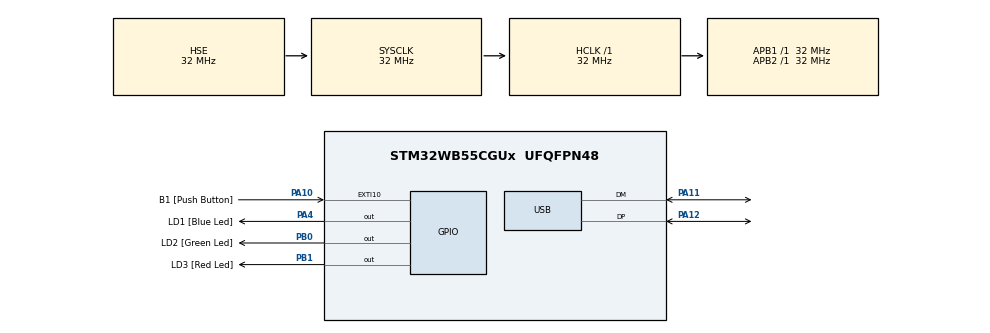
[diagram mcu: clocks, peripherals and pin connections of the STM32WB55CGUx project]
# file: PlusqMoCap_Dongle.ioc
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Mcu.Family=STM32WB
Mcu.Name=STM32WB55CGUx
Mcu.Package=UFQFPN48
NVIC.EXTI15_10_IRQn=true\:0\:0\:false\:false\:true\:true\:true
NVIC.PriorityGroup=NVIC_PRIORITYGROUP_4
NVIC.RTC_WKUP_IRQn=true\:0\:0\:false\:false\:true\:true\:true
NVIC.USB_HP_IRQn=true\:0\:0\:false\:false\:true\:true\:true
NVIC.USB_LP_IRQn=true\:0\:0\:false\:false\:true\:false\:true
OSC_IN.Mode=HSE-External-Oscillator
OSC_IN.Signal=RCC_OSC_IN
OSC_OUT.Mode=HSE-External-Oscillator
OSC_OUT.Signal=RCC_OSC_OUT
PA10.GPIO_Label=B1 [Push Button]
PA10.GPIO_ModeDefaultEXTI=GPIO_MODE_IT_FALLING
PA10.GPIO_PuPd=GPIO_PULLUP
PA10.Signal=GPXTI10
PA11.Mode=Device
PA11.Signal=USB_DM
PA12.Mode=Device
PA12.Signal=USB_DP
PA13.GPIO_Label=JTMS
PA13.Mode=Trace_Asynchronous_SW
PA13.Signal=SYS_JTMS-SWDIO
PA14.GPIO_Label=JTCK
PA14.Mode=Trace_Asynchronous_SW
PA14.Signal=SYS_JTCK-SWCLK
PA4.GPIO_Label=LD1 [Blue Led]
PA4.Signal=GPIO_Output
PB0.GPIO_Label=LD2 [Green Led]
PB0.Signal=GPIO_Output
PB1.GPIO_Label=LD3 [Red Led]
PB1.Signal=GPIO_Output
PB3.GPIO_Label=JTDO
PB3.Mode=Trace_Asynchronous_SW
PB3.Signal=SYS_JTDO-SWO
PC14-OSC32_IN.Mode=LSE-External-Oscillator
PC14-OSC32_IN.Signal=RCC_OSC32_IN
PC15-OSC32_OUT.Mode=LSE-External-Oscillator
PC15-OSC32_OUT.Signal=RCC_OSC32_OUT
ProjectManager.HeapSize=0x200
ProjectManager.StackSize=0x400
ProjectManager.TargetToolchain=STM32CubeIDE
RCC.ADCFreq_Value=160000000
RCC.AHBFreq_Value=32000000
RCC.APB1Freq_Value=32000000
RCC.APB1TimFreq_Value=32000000
RCC.APB2Freq_Value=32000000
RCC.APB2TimFreq_Value=32000000
RCC.APB3Freq_Value=16000000
RCC.CK48CLockSelection=RCC_USBCLKSOURCE_HSI48
RCC.CortexFreq_Value=32000000
RCC.HCLKFreq_Value=32000000
RCC.HSE_VALUE=32000000
RCC.HSI48_VALUE=48000000
RCC.HSI_VALUE=16000000
RCC.PLLM=RCC_PLLM_DIV2
RCC.PLLN=16
RCC.PLLQ=RCC_PLLQ_DIV4
RCC.PLLSAI1N=20
RCC.PLLSAI1Q=RCC_PLLQ_DIV5
RCC.PLLSourceVirtual=RCC_PLLSOURCE_HSE
RCC.RFWKPClockSelection=RCC_RFWKPCLKSOURCE_LSE
RCC.RTCClockSelection=RCC_RTCCLKSOURCE_LSE
RCC.SMPSCLockSelectionVirtual=RCC_SMPSCLKSOURCE_HSE
RCC.SMPSDivider=4
RCC.SYSCLKFreq_VALUE=32000000
RCC.SYSCLKSource=RCC_SYSCLKSOURCE_HSE
RCC.USBFreq_Value=48000000
RCC.VCOOutputFreq_Value=256000000
RF1.Mode=RF1_Activate
RF1.Signal=RF_RF1
STM32_WPAN.BLE_APPLICATION_TYPE=BLE_CLIENT_PROFILE
STM32_WPAN.CFG_FAST_CONN_ADV_INTERVAL_MAX_HEXA=0x0
STM32_WPAN.CFG_FAST_CONN_ADV_INTERVAL_MIN_HEXA=0x0
STM32_WPAN.CFG_LP_CONN_ADV_INTERVAL_MAX_HEXA=0x0
STM32_WPAN.CFG_LP_CONN_ADV_INTERVAL_MIN_HEXA=0x0
STM32_WPAN.LOCAL_NAME_FORMATTED=,'0'
USB.Sof_enable=DISABLE
USB_DEVICE.CLASS_NAME_FS=CDC
USB_DEVICE.VirtualMode=Cdc
USB_DEVICE.VirtualModeFS=Cdc_FS
VP_HSEM_VS_HSEM.Mode=HSEM_Activate
VP_RTC_VS_RTC_Activate.Mode=RTC_Enabled
VP_RTC_VS_RTC_WakeUp_intern.Mode=WakeUp
VP_STM32_WPAN_VS_BLE_HOST.Mode=STM32_WPAN_Enabled
VP_USB_DEVICE_VS_USB_DEVICE_CDC_FS.Mode=CDC_FS
board=P-NUCLEO-WB55-USBDongle

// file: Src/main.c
/* USER CODE BEGIN Header */
/**
  ******************************************************************************
  * @file           : main.c
  * @brief          : Main program body
  ******************************************************************************
  * @attention
  *
  * <h2><center>&copy; Copyright (c) 2019 STMicroelectronics.
  * All rights reserved.</center></h2>
  *
  * This software component is licensed by ST under BSD 3-Clause license,
  * the "License"; You may not use this file except in compliance with the
  * License. You may obtain a copy of the License at:
  *                        opensource.org/licenses/BSD-3-Clause
  *
  ******************************************************************************
  */
/* USER CODE END Header */

#include "main.h"
#include "app_entry.h"
//#include "usb_device.h"

/* USER CODE BEGIN Includes */
#include "vcp.h"
#include "scheduler.h"
#include "app_conf.h"
/* USER CODE END Includes */

RTC_HandleTypeDef hrtc;

/* USER CODE BEGIN PV */
uint8_t	usb_tx_buffer[2048], usb_rx_buffer[2048];
/* USER CODE END PV */

void SystemClock_Config(void);
static void MX_GPIO_Init(void);
static void MX_RF_Init(void);
static void MX_RTC_Init(void);
/* USER CODE BEGIN PFP */
//void dummy_callback(void)
//{
//
//}
/* USER CODE END PFP */

int main(void)
{

  /* MCU Configuration--------------------------------------------------------*/

  /* Reset of all peripherals, Initializes the Flash interface and the Systick. */
  HAL_Init();

  /* Configure the system clock */
  SystemClock_Config();

  /* Initialize all configured peripherals */
  MX_GPIO_Init();
  MX_RF_Init();
  MX_RTC_Init();
//  MX_USB_Device_Init();
  /* USER CODE BEGIN 2 */

  VCP_Init(usb_tx_buffer, usb_rx_buffer);

  /* USER CODE END 2 */
//  uint8_t test_text[] = "test!\n";
  APPE_Init();

  /* Infinite loop */
  /* USER CODE BEGIN WHILE */

  while (1)
  {

	  SCH_Run(~0);
    /* USER CODE END WHILE */

  }
}

void SystemClock_Config(void)
{
  RCC_OscInitTypeDef RCC_OscInitStruct = {0};
  RCC_ClkInitTypeDef RCC_ClkInitStruct = {0};
  RCC_PeriphCLKInitTypeDef PeriphClkInitStruct = {0};

  /** Configure LSE Drive Capability
  */
  __HAL_RCC_LSEDRIVE_CONFIG(RCC_LSEDRIVE_LOW);
  /** Configure the main internal regulator output voltage
  */
  __HAL_PWR_VOLTAGESCALING_CONFIG(PWR_REGULATOR_VOLTAGE_SCALE1);
  /** Initializes the CPU, AHB and APB busses clocks
  */
  RCC_OscInitStruct.OscillatorType = RCC_OSCILLATORTYPE_HSI48|RCC_OSCILLATORTYPE_HSI
                              |RCC_OSCILLATORTYPE_HSE|RCC_OSCILLATORTYPE_LSE;
  RCC_OscInitStruct.HSEState = RCC_HSE_ON;
  RCC_OscInitStruct.LSEState = RCC_LSE_ON;
  RCC_OscInitStruct.HSIState = RCC_HSI_ON;
  RCC_OscInitStruct.HSI48State = RCC_HSI48_ON;
  RCC_OscInitStruct.HSICalibrationValue = RCC_HSICALIBRATION_DEFAULT;
  RCC_OscInitStruct.PLL.PLLState = RCC_PLL_NONE;
  if (HAL_RCC_OscConfig(&RCC_OscInitStruct) != HAL_OK)
  {
    Error_Handler();
  }
  /** Configure the SYSCLKSource, HCLK, PCLK1 and PCLK2 clocks dividers
  */
  RCC_ClkInitStruct.ClockType = RCC_CLOCKTYPE_HCLK4|RCC_CLOCKTYPE_HCLK2
                              |RCC_CLOCKTYPE_HCLK|RCC_CLOCKTYPE_SYSCLK
                              |RCC_CLOCKTYPE_PCLK1|RCC_CLOCKTYPE_PCLK2;
  RCC_ClkInitStruct.SYSCLKSource = RCC_SYSCLKSOURCE_HSE;
  RCC_ClkInitStruct.AHBCLKDivider = RCC_SYSCLK_DIV1;
  RCC_ClkInitStruct.APB1CLKDivider = RCC_HCLK_DIV1;
  RCC_ClkInitStruct.APB2CLKDivider = RCC_HCLK_DIV1;
  RCC_ClkInitStruct.AHBCLK2Divider = RCC_SYSCLK_DIV1;
  RCC_ClkInitStruct.AHBCLK4Divider = RCC_SYSCLK_DIV1;

  if (HAL_RCC_ClockConfig(&RCC_ClkInitStruct, FLASH_LATENCY_1) != HAL_OK)
  {
    Error_Handler();
  }
  /** Initializes the peripherals clocks
  */
  PeriphClkInitStruct.PeriphClockSelection = RCC_PERIPHCLK_SMPS|RCC_PERIPHCLK_RFWAKEUP
                              |RCC_PERIPHCLK_RTC|RCC_PERIPHCLK_USB;
  PeriphClkInitStruct.UsbClockSelection = RCC_USBCLKSOURCE_HSI48;
  PeriphClkInitStruct.RTCClockSelection = RCC_RTCCLKSOURCE_LSE;
  PeriphClkInitStruct.RFWakeUpClockSelection = RCC_RFWKPCLKSOURCE_LSE;
  PeriphClkInitStruct.SmpsClockSelection = RCC_SMPSCLKSOURCE_HSE;
  PeriphClkInitStruct.SmpsDivSelection = RCC_SMPSCLKDIV_RANGE1;

  if (HAL_RCCEx_PeriphCLKConfig(&PeriphClkInitStruct) != HAL_OK)
  {
    Error_Handler();
  }
}

static void MX_RF_Init(void)
{

}

static void MX_RTC_Init(void)
{

  /** Initialize RTC Only
  */
  hrtc.Instance = RTC;
  hrtc.Init.HourFormat = RTC_HOURFORMAT_24;
  hrtc.Init.AsynchPrediv = 127;
  hrtc.Init.SynchPrediv = 255;
  hrtc.Init.OutPut = RTC_OUTPUT_DISABLE;
  hrtc.Init.OutPutRemap = RTC_OUTPUT_REMAP_NONE;
  hrtc.Init.OutPutPolarity = RTC_OUTPUT_POLARITY_HIGH;
  hrtc.Init.OutPutType = RTC_OUTPUT_TYPE_OPENDRAIN;
  if (HAL_RTC_Init(&hrtc) != HAL_OK)
  {
    Error_Handler();
  }
  /** Enable the WakeUp
  */
  if (HAL_RTCEx_SetWakeUpTimer_IT(&hrtc, 0, RTC_WAKEUPCLOCK_RTCCLK_DIV16) != HAL_OK)
  {
    Error_Handler();
  }

}

static void MX_GPIO_Init(void)
{
  GPIO_InitTypeDef GPIO_InitStruct = {0};

  /* GPIO Ports Clock Enable */
  __HAL_RCC_GPIOC_CLK_ENABLE();
  __HAL_RCC_GPIOA_CLK_ENABLE();
  __HAL_RCC_GPIOB_CLK_ENABLE();

  /*Configure GPIO pin Output Level */
  HAL_GPIO_WritePin(LD1_GPIO_Port, LD1_Pin, GPIO_PIN_RESET);

  /*Configure GPIO pin Output Level */
  HAL_GPIO_WritePin(GPIOB, LD2_Pin|LD3_Pin, GPIO_PIN_RESET);

  /*Configure GPIO pin : LD1_Pin */
  GPIO_InitStruct.Pin = LD1_Pin;
  GPIO_InitStruct.Mode = GPIO_MODE_OUTPUT_PP;
  GPIO_InitStruct.Pull = GPIO_NOPULL;
  GPIO_InitStruct.Speed = GPIO_SPEED_FREQ_LOW;
  HAL_GPIO_Init(LD1_GPIO_Port, &GPIO_InitStruct);

  /*Configure GPIO pins : LD2_Pin LD3_Pin */
  GPIO_InitStruct.Pin = LD2_Pin|LD3_Pin;
  GPIO_InitStruct.Mode = GPIO_MODE_OUTPUT_PP;
  GPIO_InitStruct.Pull = GPIO_NOPULL;
  GPIO_InitStruct.Speed = GPIO_SPEED_FREQ_LOW;
  HAL_GPIO_Init(GPIOB, &GPIO_InitStruct);

  /*Configure GPIO pin : B1_Pin */
  GPIO_InitStruct.Pin = B1_Pin;
  GPIO_InitStruct.Mode = GPIO_MODE_IT_FALLING;
  GPIO_InitStruct.Pull = GPIO_PULLUP;
  HAL_GPIO_Init(B1_GPIO_Port, &GPIO_InitStruct);

  /* EXTI interrupt init*/
  HAL_NVIC_SetPriority(EXTI15_10_IRQn, 0, 0);
  HAL_NVIC_EnableIRQ(EXTI15_10_IRQn);

}

void Error_Handler(void)
{
  /* USER CODE BEGIN Error_Handler_Debug */
  /* User can add his own implementation to report the HAL error return state */
	while(1)
	{
		// Error handler
		;
	}
  /* USER CODE END Error_Handler_Debug */
}

/************************ (C) COPYRIGHT STMicroelectronics *****END OF FILE****/
